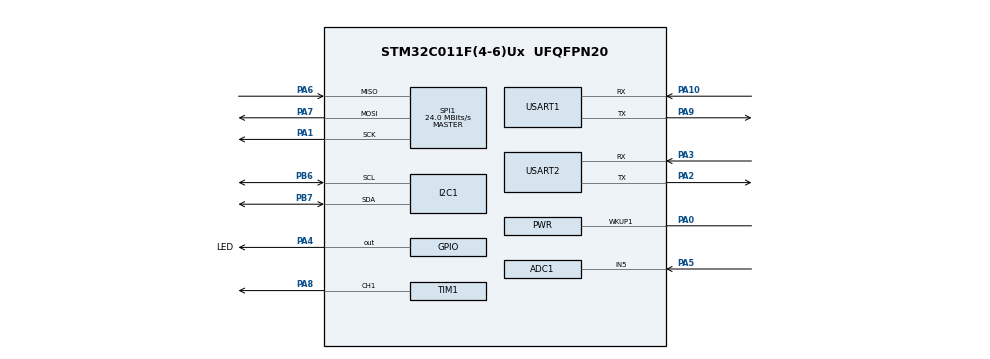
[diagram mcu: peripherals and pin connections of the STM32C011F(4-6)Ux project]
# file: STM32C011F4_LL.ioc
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ADC1.Channel-0\#ChannelRegularConversion=ADC_CHANNEL_TEMPSENSOR
ADC1.Channel-1\#ChannelRegularConversion=ADC_CHANNEL_5
ADC1.ClockPrescaler=ADC_CLOCK_SYNC_PCLK_DIV4
ADC1.NbrOfConversion=2
ADC1.NbrOfConversionFlag=1
ADC1.OffsetNumber-0\#ChannelRegularConversion=ADC_OFFSET_NONE
ADC1.OffsetNumber-1\#ChannelRegularConversion=ADC_OFFSET_NONE
ADC1.OversamplingMode=ENABLE
ADC1.Rank-0\#ChannelRegularConversion=1
ADC1.Rank-1\#ChannelRegularConversion=2
ADC1.Ratio=ADC_OVERSAMPLING_RATIO_64
ADC1.RightBitShift=ADC_RIGHTBITSHIFT_6
ADC1.SamplingTime-0\#ChannelRegularConversion=ADC_SAMPLINGTIME_COMMON_1
ADC1.SamplingTime-1\#ChannelRegularConversion=ADC_SAMPLINGTIME_COMMON_1
ADC1.SamplingTimeCommon1=ADC_SAMPLETIME_160CYCLES_5
ADC1.SamplingTimeCommon2=ADC_SAMPLETIME_160CYCLES_5
ADC1.SelectedChannel=ADC_CHANNEL_5|ADC_CHANNEL_TEMPSENSOR
ADC1.Sequencer=FULLY_CONFIGURABLE
ADC1.master=1
I2C1.Timing=0x10805D88
Mcu.Family=STM32C0
Mcu.Name=STM32C011F(4-6)Ux
Mcu.Package=UFQFPN20
PA0.Mode=WakeUp1
PA0.Signal=PWR_WKUP1
PA1.Mode=Full_Duplex_Master
PA1.Signal=SPI1_SCK
PA10\ [PA12].Mode=Asynchronous
PA10\ [PA12].Signal=USART1_RX
PA13.Mode=Serial_Wire
PA13.Signal=DEBUG_SWDIO
PA14-BOOT0.Mode=Serial_Wire
PA14-BOOT0.Signal=DEBUG_SWCLK
PA2.Mode=Asynchronous
PA2.Signal=USART2_TX
PA3.Mode=Asynchronous
PA3.Signal=USART2_RX
PA4.GPIO_Label=LED
PA4.Signal=GPIO_Output
PA5.Mode=IN5
PA5.Signal=ADC1_IN5
PA6.Mode=Full_Duplex_Master
PA6.Signal=SPI1_MISO
PA7.Mode=Full_Duplex_Master
PA7.Signal=SPI1_MOSI
PA8.Signal=S_TIM1_CH1
PA9\ [PA11].Mode=Asynchronous
PA9\ [PA11].Signal=USART1_TX
PB6.Mode=I2C
PB6.Signal=I2C1_SCL
PB7.Mode=I2C
PB7.Signal=I2C1_SDA
PC14-OSCX_IN\ (PC14).Mode=LSE-External-Oscillator
PC14-OSCX_IN\ (PC14).Signal=RCC_OSCX_IN
PC15-OSCX_OUT\ (PC15).Mode=LSE-External-Oscillator
PC15-OSCX_OUT\ (PC15).Signal=RCC_OSCX_OUT
ProjectManager.HeapSize=0x200
ProjectManager.StackSize=0x400
ProjectManager.TargetToolchain=STM32CubeIDE
RCC.ADCFreq_Value=48000000
RCC.AHBFreq_Value=48000000
RCC.CortexFreq_Value=48000000
RCC.EXTERNAL_CLOCK_VALUE=12288000
RCC.HCLKFreq_Value=48000000
RCC.HSE_VALUE=48000000
RCC.HSISYSCLKDivider=RCC_HSI_DIV1
RCC.HSI_VALUE=48000000
RCC.SYSCLKFreq_VALUE=48000000
SH.S_TIM1_CH1.0=TIM1_CH1,PWM Generation1 CH1
SPI1.CalculateBaudRate=24.0 MBits/s
SPI1.Direction=SPI_DIRECTION_2LINES
SPI1.Mode=SPI_MODE_MASTER
SPI1.VirtualType=VM_MASTER
TIM1.Channel-PWM\ Generation1\ CH1=TIM_CHANNEL_1
USART1.VirtualMode-Asynchronous=VM_ASYNC
USART2.VirtualMode-Asynchronous=VM_ASYNC
VP_ADC1_TempSens_Input.Mode=IN-TempSens
VP_SYS_VS_PINREMAP.Mode=PINREMAP
VP_SYS_VS_PINREMAP_10_12.Mode=PINREMAP_10_12
board=custom

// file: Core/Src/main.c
/* USER CODE BEGIN Header */
/**
  ******************************************************************************
  * @file           : main.c
  * @brief          : Main program body
  ******************************************************************************
  * @attention
  *
  * Copyright (c) 2026 STMicroelectronics.
  * All rights reserved.
  *
  * This software is licensed under terms that can be found in the LICENSE file
  * in the root directory of this software component.
  * If no LICENSE file comes with this software, it is provided AS-IS.
  *
  ******************************************************************************
  */
/* USER CODE END Header */
#include "main.h"
#include "adc.h"
#include "i2c.h"
#include "spi.h"
#include "tim.h"
#include "usart.h"
#include "gpio.h"

/* USER CODE BEGIN PD */
#define dormir 1
/* USER CODE END PD */

/* USER CODE BEGIN PV */
volatile uint32_t uwTick;

/* USER CODE END PV */

void SystemClock_Config(void);

int main(void)
{

  /* MCU Configuration--------------------------------------------------------*/

  /* Reset of all peripherals, Initializes the Flash interface and the Systick. */
  LL_APB2_GRP1_EnableClock(LL_APB2_GRP1_PERIPH_SYSCFG);
  LL_APB1_GRP1_EnableClock(LL_APB1_GRP1_PERIPH_PWR);

  /* SysTick_IRQn interrupt configuration */
  NVIC_SetPriority(SysTick_IRQn, 3);

  LL_SYSCFG_EnablePinRemap(LL_SYSCFG_PIN_RMP_PA11);
  LL_SYSCFG_EnablePinRemap(LL_SYSCFG_PIN_RMP_PA12);

  /* Configure the system clock */
  SystemClock_Config();

  /* Initialize all configured peripherals */
  MX_GPIO_Init();
  MX_ADC1_Init();
  MX_I2C1_Init();
  MX_SPI1_Init();
  MX_TIM1_Init();
  MX_USART1_UART_Init();
  MX_USART2_UART_Init();
  /* USER CODE BEGIN 2 */
  uint32_t lastTick = 0;
  uint8_t boolarray=0;
  /* USER CODE END 2 */

  /* Infinite loop */
  /* USER CODE BEGIN WHILE */

  while (1)
  {
	  boolarray&=!dormir; //si nadie cambia la bandera deberia ir a dormir (pendiente)
	  LL_GPIO_SetOutputPin(LED_GPIO_Port,LED_Pin);
	  LL_TIM_OC_SetCompareCH1(TIM1, 65535);   // duty = valor entre 0 y ARR
	  LL_mDelay(500);
	  //LL_GPIO_TogglePin(LED_GPIO_Port, LED_Pin);
	  LL_GPIO_ResetOutputPin(LED_GPIO_Port, LED_Pin);
	  LL_TIM_OC_SetCompareCH1(TIM1, 32768);
	  LL_mDelay(500);
    /* USER CODE END WHILE */
  }
}

void SystemClock_Config(void)
{

  LL_FLASH_SetLatency(LL_FLASH_LATENCY_1);

  /* HSI configuration and activation */
  LL_RCC_HSI_Enable();
  while(LL_RCC_HSI_IsReady() != 1)
  {
  }

  LL_RCC_HSI_SetCalibTrimming(64);
  LL_RCC_SetHSIDiv(LL_RCC_HSI_DIV_1);
  /* Set AHB prescaler*/
  LL_RCC_SetAHBPrescaler(LL_RCC_HCLK_DIV_1);

  /* Sysclk activation on the HSI */
  LL_RCC_SetSysClkSource(LL_RCC_SYS_CLKSOURCE_HSI);
  while(LL_RCC_GetSysClkSource() != LL_RCC_SYS_CLKSOURCE_STATUS_HSI)
  {
  }

  /* Set APB1 prescaler*/
  LL_RCC_SetAPB1Prescaler(LL_RCC_APB1_DIV_1);
  LL_Init1msTick(48000000);
  /* Update CMSIS variable (which can be updated also through SystemCoreClockUpdate function) */
  LL_SetSystemCoreClock(48000000);
}

void Error_Handler(void)
{
  __disable_irq();
  while (1)
  {
  }
}
